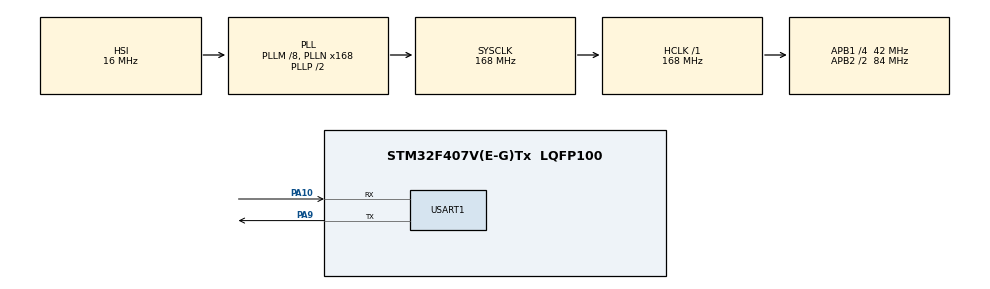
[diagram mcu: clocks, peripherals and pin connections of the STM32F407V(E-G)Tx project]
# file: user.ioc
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Mcu.Family=STM32F4
Mcu.Name=STM32F407V(E-G)Tx
Mcu.Package=LQFP100
NVIC.PriorityGroup=NVIC_PRIORITYGROUP_4
NVIC.USART1_IRQn=true\:0\:0\:false\:false\:true\:true\:true\:true
PA10.Mode=Asynchronous
PA10.Signal=USART1_RX
PA9.Mode=Asynchronous
PA9.Signal=USART1_TX
PH0-OSC_IN.Mode=HSE-External-Oscillator
PH0-OSC_IN.Signal=RCC_OSC_IN
PH1-OSC_OUT.Mode=HSE-External-Oscillator
PH1-OSC_OUT.Signal=RCC_OSC_OUT
ProjectManager.HeapSize=0x200
ProjectManager.StackSize=0x400
ProjectManager.TargetToolchain=MDK-ARM V5.32
RCC.48MHZClocksFreq_Value=84000000
RCC.AHBFreq_Value=168000000
RCC.APB1CLKDivider=RCC_HCLK_DIV4
RCC.APB1Freq_Value=42000000
RCC.APB1TimFreq_Value=84000000
RCC.APB2CLKDivider=RCC_HCLK_DIV2
RCC.APB2Freq_Value=84000000
RCC.APB2TimFreq_Value=168000000
RCC.CortexFreq_Value=168000000
RCC.HCLKFreq_Value=168000000
RCC.HSE_VALUE=8000000
RCC.HSI_VALUE=16000000
RCC.LSE_VALUE=32768
RCC.PLLM=8
RCC.PLLN=168
RCC.SYSCLKFreq_VALUE=168000000
RCC.SYSCLKSource=RCC_SYSCLKSOURCE_PLLCLK
RCC.VCOOutputFreq_Value=336000000
USART1.VirtualMode=VM_ASYNC
board=custom

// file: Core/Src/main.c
/* USER CODE BEGIN Header */
/**
 ******************************************************************************
 * @file           : main.c
 * @brief          : Main program body
 ******************************************************************************
 * @attention
 *
 * Copyright (c) 2025 STMicroelectronics.
 * All rights reserved.
 *
 * This software is licensed under terms that can be found in the LICENSE file
 * in the root directory of this software component.
 * If no LICENSE file comes with this software, it is provided AS-IS.
 *
 ******************************************************************************
 */
/* USER CODE END Header */
#include "main.h"

/* USER CODE BEGIN Includes */
#include "stdio.h"
#include "string.h"
#include <stm32f4xx_hal_uart.h>
/* USER CODE END Includes */

UART_HandleTypeDef huart1;

/* USER CODE BEGIN PV */
// char input = 0;
// char flag = 0;
// char name[15] = { 0 };
// char username[15] = { 0 };
// char username1[15] = { 0 };
// char pass[15] = { 0 };
// char pass1[15] = { 0 };
// char i = 0;

char reg_name[8];
char reg_username[8];
char reg_password[8];

char input_username[8];
char input_password[8];
/* USER CODE END PV */

void SystemClock_Config(void);
static void MX_GPIO_Init(void);
static void MX_USART1_UART_Init(void);

/* USER CODE BEGIN 0 */
// void HAL_UART_RxCpltCallback(UART_HandleTypeDef* huart)
// {
// 	HAL_UART_Transmit(&huart1, &input, 1, 100);
// 	HAL_UART_Receive_IT(&huart1, &input, 1);
// }

void uart_send(const char* msg)
{
	HAL_UART_Transmit(&huart1, (uint8_t*)msg, strlen(msg), HAL_MAX_DELAY);
}

void uart_receive_line(char* buf, uint16_t maxlen)
{
	uint16_t idx = 0;
	char ch;
	while (idx < maxlen - 1)
	{
		if (HAL_UART_Receive(&huart1, &ch, 1, HAL_MAX_DELAY) == HAL_OK)
		{
			if (ch == '\r' || ch == '\n')
				break;
			buf[idx++] = ch;
			HAL_UART_Transmit(&huart1, (uint8_t*)&ch, 1, HAL_MAX_DELAY);
			// uart_send((char*)&ch);
		}
	}
	buf[idx] = '\0';
}

/* USER CODE END 0 */

int main(void)
{

	/* MCU Configuration--------------------------------------------------------*/

	/* Reset of all peripherals, Initializes the Flash interface and the Systick. */
	HAL_Init();

	/* Configure the system clock */
	SystemClock_Config();

	/* Initialize all configured peripherals */
	MX_GPIO_Init();
	MX_USART1_UART_Init();
	/* USER CODE BEGIN 2 */
	// user();

	uart_send("Enter your Name: ");
	uart_receive_line(reg_name, 8);

	uart_send("\r\nEnter Username: ");
	uart_receive_line(reg_username, 8);

	uart_send("\r\nEnter Password: ");
	uart_receive_line(reg_password, 8);

	uart_send("\r\nLogin\r\n");

	uart_send("Username: ");
	uart_receive_line(input_username, 8);

	uart_send("\r\nPassword: ");
	uart_receive_line(input_password, 8);

	if (strcmp(reg_username, input_username) == 0 && strcmp(reg_password, input_password) == 0)
	{
		uart_send("\r\nWelcome, ");
		uart_send(reg_name);
		uart_send("\r\n");
	}
	else
	{
		uart_send("\r\nError: Invalid Username or Password\r\n");
	}
	/* USER CODE END 2 */

	/* Infinite loop */
	while (1)
	{

	}
}

void SystemClock_Config(void)
{
	RCC_OscInitTypeDef RCC_OscInitStruct = { 0 };
	RCC_ClkInitTypeDef RCC_ClkInitStruct = { 0 };

	/** Configure the main internal regulator output voltage
	 */
	__HAL_RCC_PWR_CLK_ENABLE();
	__HAL_PWR_VOLTAGESCALING_CONFIG(PWR_REGULATOR_VOLTAGE_SCALE1);

	/** Initializes the RCC Oscillators according to the specified parameters
	 * in the RCC_OscInitTypeDef structure.
	 */
	RCC_OscInitStruct.OscillatorType = RCC_OSCILLATORTYPE_HSI;
	RCC_OscInitStruct.HSIState = RCC_HSI_ON;
	RCC_OscInitStruct.HSICalibrationValue = RCC_HSICALIBRATION_DEFAULT;
	RCC_OscInitStruct.PLL.PLLState = RCC_PLL_ON;
	RCC_OscInitStruct.PLL.PLLSource = RCC_PLLSOURCE_HSI;
	RCC_OscInitStruct.PLL.PLLM = 8;
	RCC_OscInitStruct.PLL.PLLN = 168;
	RCC_OscInitStruct.PLL.PLLP = RCC_PLLP_DIV2;
	RCC_OscInitStruct.PLL.PLLQ = 4;
	if (HAL_RCC_OscConfig(&RCC_OscInitStruct) != HAL_OK)
	{
		Error_Handler();
	}

	/** Initializes the CPU, AHB and APB buses clocks
	 */
	RCC_ClkInitStruct.ClockType = RCC_CLOCKTYPE_HCLK | RCC_CLOCKTYPE_SYSCLK
		| RCC_CLOCKTYPE_PCLK1 | RCC_CLOCKTYPE_PCLK2;
	RCC_ClkInitStruct.SYSCLKSource = RCC_SYSCLKSOURCE_PLLCLK;
	RCC_ClkInitStruct.AHBCLKDivider = RCC_SYSCLK_DIV1;
	RCC_ClkInitStruct.APB1CLKDivider = RCC_HCLK_DIV4;
	RCC_ClkInitStruct.APB2CLKDivider = RCC_HCLK_DIV2;

	if (HAL_RCC_ClockConfig(&RCC_ClkInitStruct, FLASH_LATENCY_5) != HAL_OK)
	{
		Error_Handler();
	}
}

static void MX_USART1_UART_Init(void)
{

	huart1.Instance = USART1;
	huart1.Init.BaudRate = 115200;
	huart1.Init.WordLength = UART_WORDLENGTH_8B;
	huart1.Init.StopBits = UART_STOPBITS_1;
	huart1.Init.Parity = UART_PARITY_NONE;
	huart1.Init.Mode = UART_MODE_TX_RX;
	huart1.Init.HwFlowCtl = UART_HWCONTROL_NONE;
	huart1.Init.OverSampling = UART_OVERSAMPLING_16;
	if (HAL_UART_Init(&huart1) != HAL_OK)
	{
		Error_Handler();
	}
}

static void MX_GPIO_Init(void)
{

	/* GPIO Ports Clock Enable */
	__HAL_RCC_GPIOH_CLK_ENABLE();
	__HAL_RCC_GPIOA_CLK_ENABLE();
}

void Error_Handler(void)
{
	__disable_irq();
	while (1)
	{
	}
}
